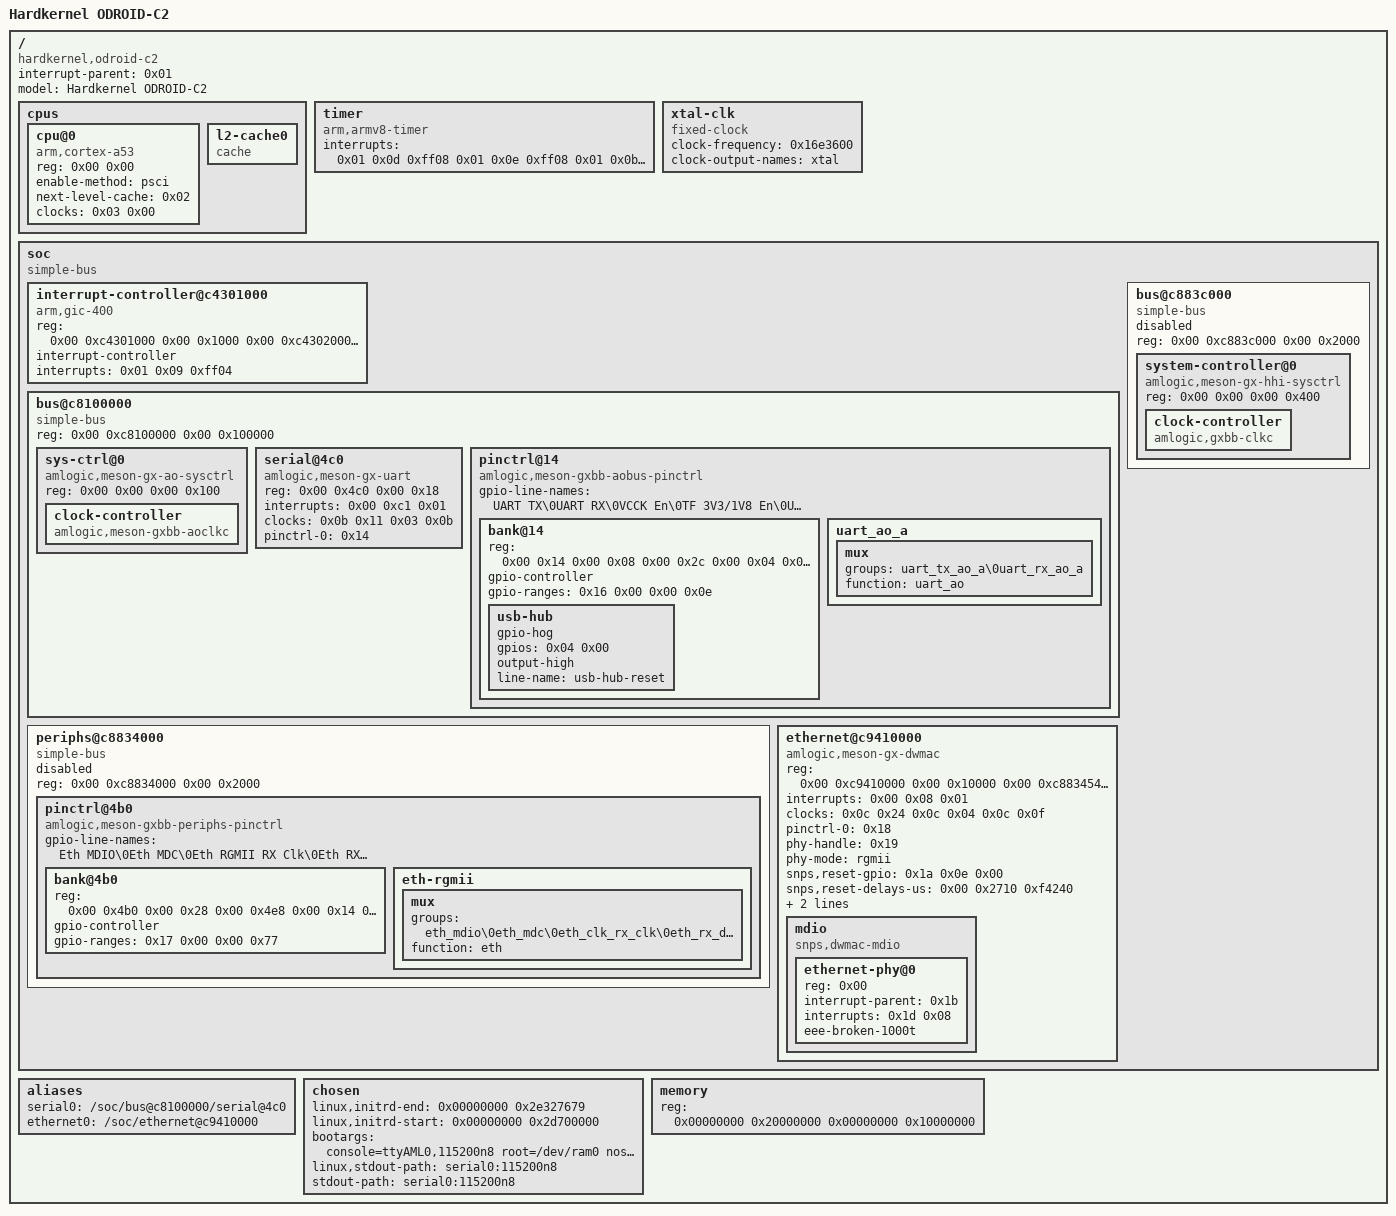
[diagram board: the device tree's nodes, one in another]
// SPDX-License-Identifier: GPL-2.0-or-later OR MIT
/*
 * Copyright (c) 2016 Andreas Färber
 * Copyright (c) 2016 BayLibre, Inc.
 * Author: Kevin Hilman <khilman@kernel.org>
 *
 * Extracted from Linux 4.20-rc7's original dts file
 */

/dts-v1/;

/ {
    interrupt-parent = <0x01>;
    #address-cells = <0x02>;
    #size-cells = <0x02>;
    compatible = "hardkernel,odroid-c2\0amlogic,meson-gxbb";
    model = "Hardkernel ODROID-C2";

    cpus {
        #address-cells = <0x02>;
        #size-cells = <0x00>;

        cpu@0 {
            device_type = "cpu";
            compatible = "arm,cortex-a53\0arm,armv8";
            reg = <0x00 0x00>;
            enable-method = "psci";
            next-level-cache = <0x02>;
            clocks = <0x03 0x00>;
            phandle = <0x04>;
        };


        l2-cache0 {
            compatible = "cache";
            phandle = <0x02>;
        };
    };

    timer {
        compatible = "arm,armv8-timer";
        interrupts = <0x01 0x0d 0xff08 0x01 0x0e 0xff08 0x01 0x0b 0xff08 0x01 0x0a 0xff08>;
    };

    xtal-clk {
        compatible = "fixed-clock";
        clock-frequency = <0x16e3600>;
        clock-output-names = "xtal";
        #clock-cells = <0x00>;
        phandle = <0x0b>;
    };

    soc {
        compatible = "simple-bus";
        #address-cells = <0x02>;
        #size-cells = <0x02>;
        ranges;


        interrupt-controller@c4301000 {
            compatible = "arm,gic-400";
            reg = <0x00 0xc4301000 0x00 0x1000 0x00 0xc4302000 0x00 0x2000 0x00 0xc4304000 0x00 0x2000 0x00 0xc4306000 0x00 0x2000>;
            interrupt-controller;
            interrupts = <0x01 0x09 0xff04>;
            #interrupt-cells = <0x03>;
            #address-cells = <0x00>;
            phandle = <0x01>;
        };


        bus@c8100000 {
            compatible = "simple-bus";
            reg = <0x00 0xc8100000 0x00 0x100000>;
            #address-cells = <0x02>;
            #size-cells = <0x02>;
            ranges = <0x00 0x00 0x00 0xc8100000 0x00 0x100000>;

            sys-ctrl@0 {
                compatible = "amlogic,meson-gx-ao-sysctrl\0simple-mfd\0syscon";
                reg = <0x00 0x00 0x00 0x100>;


                clock-controller {
                    compatible = "amlogic,meson-gxbb-aoclkc\0amlogic,meson-gx-aoclkc";
                    #clock-cells = <0x01>;
                    #reset-cells = <0x01>;
                    phandle = <0x11>;
                };
            };



            serial@4c0 {
                compatible = "amlogic,meson-gx-uart\0amlogic,meson-ao-uart";
                reg = <0x00 0x4c0 0x00 0x18>;
                interrupts = <0x00 0xc1 0x01>;
                status = "okay";
                clocks = <0x0b 0x11 0x03 0x0b>;
                clock-names = "xtal\0pclk\0baud";
                pinctrl-0 = <0x14>;
                pinctrl-names = "default";
            };


            pinctrl@14 {
                compatible = "amlogic,meson-gxbb-aobus-pinctrl";
                #address-cells = <0x02>;
                #size-cells = <0x02>;
                ranges;
                gpio-line-names = "UART TX\0UART RX\0VCCK En\0TF 3V3/1V8 En\0USB HUB nRESET\0USB OTG Power En\0J7 Header Pin2\0IR In\0J7 Header Pin4\0J7 Header Pin6\0J7 Header Pin5\0J7 Header Pin7\0HDMI CEC\0SYS LED\0";
                phandle = <0x16>;

                bank@14 {
                    reg = <0x00 0x14 0x00 0x08 0x00 0x2c 0x00 0x04 0x00 0x24 0x00 0x08>;
                    reg-names = "mux\0pull\0gpio";
                    gpio-controller;
                    #gpio-cells = <0x02>;
                    gpio-ranges = <0x16 0x00 0x00 0x0e>;
                    phandle = <0x2e>;

                    usb-hub {
                        gpio-hog;
                        gpios = <0x04 0x00>;
                        output-high;
                        line-name = "usb-hub-reset";
                    };
                };

                uart_ao_a {
                    phandle = <0x14>;

                    mux {
                        groups = "uart_tx_ao_a\0uart_rx_ao_a";
                        function = "uart_ao";
                    };
                };

            };
        };

        periphs@c8834000 {
            compatible = "simple-bus";
            reg = <0x00 0xc8834000 0x00 0x2000>;
            #address-cells = <0x02>;
            #size-cells = <0x02>;
            ranges = <0x00 0x00 0x00 0xc8834000 0x00 0x2000>;
            status = "disabled";

            pinctrl@4b0 {
                compatible = "amlogic,meson-gxbb-periphs-pinctrl";
                #address-cells = <0x02>;
                #size-cells = <0x02>;
                ranges;
                gpio-line-names = "Eth MDIO\0Eth MDC\0Eth RGMII RX Clk\0Eth RX DV\0Eth RX D0\0Eth RX D1\0Eth RX D2\0Eth RX D3\0Eth RGMII TX Clk\0Eth TX En\0Eth TX D0\0Eth TX D1\0Eth TX D2\0Eth TX D3\0Eth PHY nRESET\0Eth PHY Intc\0HDMI HPD\0HDMI DDC SDA\0HDMI DDC SCL\0\0eMMC D0\0eMMC D1\0eMMC D2\0eMMC D3\0eMMC D4\0eMMC D5\0eMMC D6\0eMMC D7\0eMMC Clk\0eMMC Reset\0eMMC CMD\0\0\0\0\0\0\0\0SDCard D1\0SDCard D0\0SDCard CLK\0SDCard CMD\0SDCard D3\0SDCard D2\0SDCard Det\0\0\0\0\0\0\0\0\0\0\0\0\0\0\0\0\0\0\0\0\0\0\0\0\0I2C A SDA\0I2C A SCK\0I2C B SDA\0I2C B SCK\0PWM D\0PWM B\0Revision Bit0\0Revision Bit1\0\0J2 Header Pin35\0\0\0\0J2 Header Pin36\0J2 Header Pin31\0\0\0\0TF VDD En\0J2 Header Pin32\0J2 Header Pin26\0\0\0J2 Header Pin29\0J2 Header Pin24\0J2 Header Pin23\0J2 Header Pin22\0J2 Header Pin21\0J2 Header Pin18\0J2 Header Pin33\0J2 Header Pin19\0J2 Header Pin16\0J2 Header Pin15\0J2 Header Pin12\0J2 Header Pin13\0J2 Header Pin8\0J2 Header Pin10\0\0\0\0\0\0J2 Header Pin11\0\0J2 Header Pin7\0\0\0\0\0";
                phandle = <0x17>;

                bank@4b0 {
                    reg = <0x00 0x4b0 0x00 0x28 0x00 0x4e8 0x00 0x14 0x00 0x520 0x00 0x14 0x00 0x430 0x00 0x40>;
                    reg-names = "mux\0pull\0pull-enable\0gpio";
                    gpio-controller;
                    #gpio-cells = <0x02>;
                    gpio-ranges = <0x17 0x00 0x00 0x77>;
                    phandle = <0x1a>;
                };

                eth-rgmii {
                    phandle = <0x18>;

                    mux {
                        groups = "eth_mdio\0eth_mdc\0eth_clk_rx_clk\0eth_rx_dv\0eth_rxd0\0eth_rxd1\0eth_rxd2\0eth_rxd3\0eth_rgmii_tx_clk\0eth_tx_en\0eth_txd0\0eth_txd1\0eth_txd2\0eth_txd3";
                        function = "eth";
                    };
                };
            };
        };


        bus@c883c000 {
            compatible = "simple-bus";
            reg = <0x00 0xc883c000 0x00 0x2000>;
            #address-cells = <0x02>;
            #size-cells = <0x02>;
            ranges = <0x00 0x00 0x00 0xc883c000 0x00 0x2000>;
            status = "disabled";

            system-controller@0 {
                compatible = "amlogic,meson-gx-hhi-sysctrl\0simple-mfd\0syscon";
                reg = <0x00 0x00 0x00 0x400>;
                phandle = <0x10>;

                clock-controller {
                    compatible = "amlogic,gxbb-clkc";
                    #clock-cells = <0x01>;
                    phandle = <0x0c>;
                };
            };

        };

        ethernet@c9410000 {
            compatible = "amlogic,meson-gx-dwmac\0amlogic,meson-gxbb-dwmac\0snps,dwmac";
            reg = <0x00 0xc9410000 0x00 0x10000 0x00 0xc8834540 0x00 0x04>;
            interrupts = <0x00 0x08 0x01>;
            interrupt-names = "macirq";
            status = "okay";
            clocks = <0x0c 0x24 0x0c 0x04 0x0c 0x0f>;
            clock-names = "stmmaceth\0clkin0\0clkin1";
            pinctrl-0 = <0x18>;
            pinctrl-names = "default";
            phy-handle = <0x19>;
            phy-mode = "rgmii";
            snps,reset-gpio = <0x1a 0x0e 0x00>;
            snps,reset-delays-us = <0x00 0x2710 0xf4240>;
            snps,reset-active-low;
            amlogic,tx-delay-ns = <0x02>;

            mdio {
                compatible = "snps,dwmac-mdio";
                #address-cells = <0x01>;
                #size-cells = <0x00>;

                ethernet-phy@0 {
                    reg = <0x00>;
                    interrupt-parent = <0x1b>;
                    interrupts = <0x1d 0x08>;
                    eee-broken-1000t;
                    phandle = <0x19>;
                };
            };
        };
    };

    aliases {
        serial0 = "/soc/bus@c8100000/serial@4c0";
        ethernet0 = "/soc/ethernet@c9410000";
    };

    chosen {
        linux,initrd-end = <0x00000000 0x2e327679>;
        linux,initrd-start = <0x00000000 0x2d700000>;
        bootargs = "console=ttyAML0,115200n8 root=/dev/ram0 nosmp rw debug loglevel=8 pci=nomsi earlyprintk=serial maxcpus=1";
        linux,stdout-path = "serial0:115200n8";
        stdout-path = "serial0:115200n8";
    };

    memory {
        reg = <0x00000000 0x20000000 0x00000000 0x10000000>;
        device_type = "memory";
    };
};
